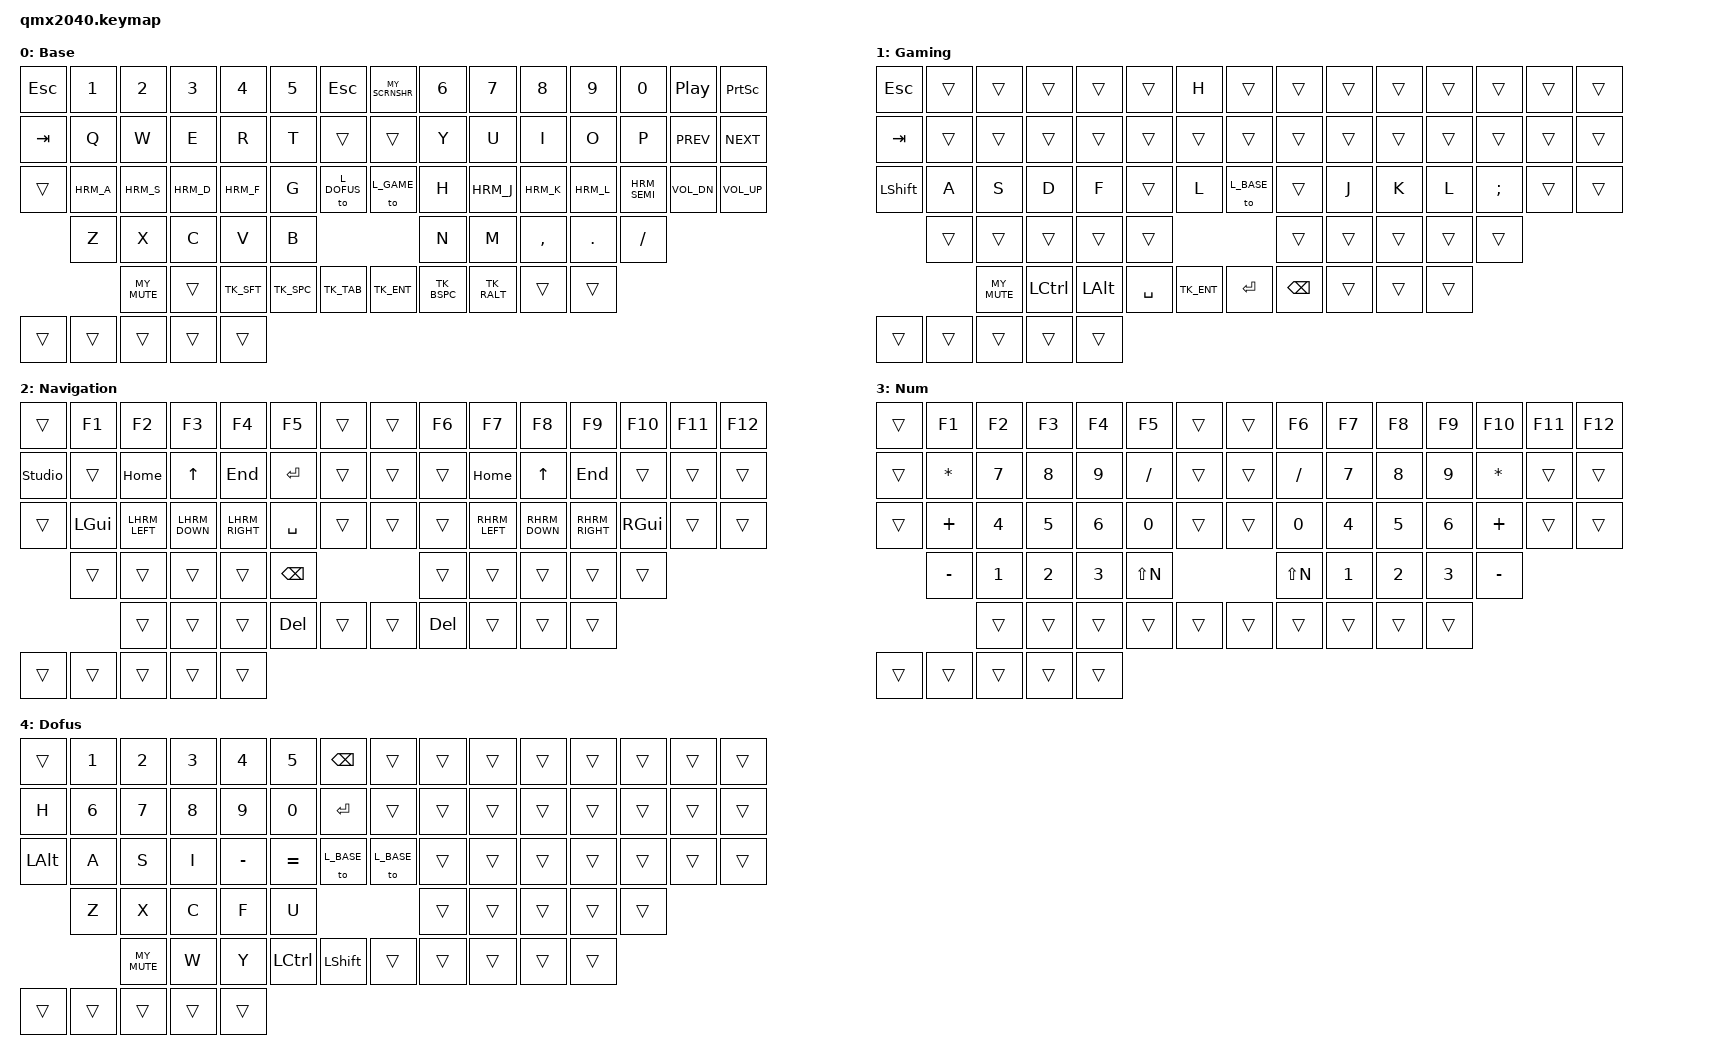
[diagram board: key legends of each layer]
#include <behaviors.dtsi>
#include <dt-bindings/zmk/keys.h>

#include <dt-bindings/zmk/oskey.h>
#include <behaviors/oskey.dtsi>


#include "config.h"



&sl { ignore-modifiers; }; // keep one-shot-mods when chained into a one-shot-layer
&sk { quick-release; };    // must-have! (lots of false positives otherwise)

// add our common tap-hold parametesr to the default options
&mt {
  tapping-term-ms = <SHORT_TAPPING_TERM>;
  quick-tap-ms = <QUICK_TAP>;
};

&lt {
  tapping-term-ms = <TAPPING_TERM>;
  quick-tap-ms = <QUICK_TAP>;
};

/ {
  behaviors {

    hrm: homerow_mods {
      compatible = "zmk,behavior-hold-tap";
      #binding-cells = <2>;
      tapping-term-ms = <TAPPING_TERM>;
      quick-tap-ms = <QUICK_TAP>;
      flavor = "tap-preferred";
      bindings = <&kp>, <&kp>;
    };

    sc: space_cadet { // same as lt, but with hold-preferred
      compatible = "zmk,behavior-hold-tap";
      #binding-cells = <2>;
      tapping-term-ms = <SHORT_TAPPING_TERM>;
      quick-tap-ms = <QUICK_TAP>;
      flavor = "hold-preferred";
      bindings = <&mo>, <&kp>;
    };

    // in case i want to do keyboard emulation of ergol
    // like ZMK's sticky layer (sl) but with a more robust timing
    // osl: one_shot_layer {
    //   compatible = "zmk,behavior-macro-one-param";
    //   #binding-cells = <1>;
    //   tap-ms = <0>;
    //   wait-ms = <0>;
    //   bindings = <&macro_param_1to1>, <&macro_tap &sl MACRO_PLACEHOLDER>;
    // };
    //  
    // bsl: better_sticky_layer {
    //   compatible = "zmk,behavior-hold-tap";
    //   #binding-cells = <2>;
    //   tapping-term-ms = <TAPPING_TERM>;
    //   flavor = "tap-preferred";
    //   bindings = <&mo>, <&osl>;
    // };

    // like ZMK's sticky key (sk) but with a more robust timing
    osm: one_shot_modifier {
      compatible = "zmk,behavior-macro-one-param";
      #binding-cells = <1>;
      tap-ms = <0>;
      wait-ms = <0>;
      bindings = <&macro_param_1to1>, <&macro_tap &sk MACRO_PLACEHOLDER>;
    };

    bsk: better_sticky_key {
      compatible = "zmk,behavior-hold-tap";
      #binding-cells = <2>;
      tapping-term-ms = <TAPPING_TERM>;
      flavor = "tap-preferred";
      bindings = <&kp>, <&osm>;
    };

    bsk_shift: bsk_shift {
      compatible = "zmk,behavior-mod-morph";
      #binding-cells = <0>;
      bindings  = <&EZ_SK(LSHFT)>, <&kp CAPSLOCK>;
      mods      = <MOD_RALT>;
      keep-mods = <MOD_RALT>;
    };

  };


  combos {
    compatible = "zmk,combos";

    combo_esc {
      timeout-ms = <30>;
      layers = <L_BASE>;
      key-positions = <39 40>;
      bindings = <&kp ESC>;
    };

  };


  keymap {
    compatible = "zmk,keymap";

    base_layer: base_layer {
      display-name = "Base";
      bindings = <
        &kp ESC   &kp N1 &kp N2  &kp N3 &kp N4 &kp N5 &kp ESC       MY_SCRNSHR &kp N6  &kp N7  &kp N8    &kp N9  &kp N0     &kp C_PP     &kp PSCRN
        &kp TAB   &kp Q  &kp W   &kp E  &kp R  &kp T  &trans        &trans     &kp Y   &kp U   &kp I     &kp O   &kp P      &kp C_PREV   &kp C_NEXT
        &trans    HRM_A  HRM_S   HRM_D  HRM_F  &kp G  &to L_DOFUS   &to L_GAME &kp H   HRM_J   HRM_K     HRM_L   HRM_SEMI   &kp C_VOL_DN &kp C_VOL_UP
                  &kp Z  &kp X   &kp C  &kp V  &kp B                           &kp N   &kp M   &kp COMMA &kp DOT &kp FSLH
                         MY_MUTE &trans TK_SFT TK_SPC TK_TAB        TK_ENT     TK_BSPC TK_RALT &trans    &trans
          &trans  &trans  &trans  &trans  &trans
      >;
    };


    layer_gaming: layer_gaming {
      display-name = "Gaming";
      bindings = <
        &kp ESC   &trans  &trans  &trans &trans   &trans  &kp H         &trans     &trans    &trans &trans &trans &trans    &trans &trans
        &kp TAB   &trans  &trans  &trans &trans   &trans  &trans        &trans     &trans    &trans &trans &trans &trans    &trans &trans
        &kp LSHFT &kp A   &kp S   &kp D  &kp F    &trans  &kp L         &to L_BASE &trans    &kp J  &kp K  &kp L  &kp SEMI  &trans &trans
                  &trans  &trans  &trans &trans   &trans                           &trans    &trans &trans &trans &trans
                          MY_MUTE &kp LCTL &kp LALT &kp SPC TK_ENT        &kp ENTER  &kp BSPC  &trans &trans &trans
          &trans  &trans  &trans  &trans  &trans
      >;
    };


    layer_nav: layer_nav {
      display-name = "Navigation";
      bindings = <
        &trans         &kp F1    &kp F2    &kp F3    &kp F4     &kp F5    &trans     &trans &kp F6  &kp F7    &kp F8    &kp F9     &kp F10   &kp F11 &kp F12
        &studio_unlock &trans    &kp HOME  &kp UP    &kp END    &kp RET   &trans     &trans &trans  &kp HOME  &kp UP    &kp END    &trans    &trans  &trans
        &trans         &kp LGUI  LHRM_LEFT LHRM_DOWN LHRM_RIGHT &kp SPC   &trans     &trans &trans  RHRM_LEFT RHRM_DOWN RHRM_RIGHT &kp RGUI  &trans  &trans
                       &trans    &trans    &trans    &trans     &kp BSPC                    &trans  &trans    &trans    &trans     &trans
                                 &trans    &trans    &trans     &kp DEL   &trans     &trans &kp DEL &trans    &trans    &trans
          &trans  &trans  &trans  &trans  &trans
      >;
    };


    layer_num: layer_num {
      display-name = "Num";
      bindings = <
        &trans &kp F1    &kp F2 &kp F3 &kp F4 &kp F5    &trans    &trans &kp F6    &kp F7 &kp F8 &kp F9 &kp F10   &kp F11 &kp F12
        &trans &kp STAR  &kp N7 &kp N8 &kp N9 &kp SLASH &trans    &trans &kp SLASH &kp N7 &kp N8 &kp N9 &kp STAR  &trans &trans
        &trans &kp PLUS  &kp N4 &kp N5 &kp N6 &kp N0    &trans    &trans &kp N0    &kp N4 &kp N5 &kp N6 &kp PLUS  &trans &trans
               &kp MINUS &kp N1 &kp N2 &kp N3 &kp LS(N)                  &kp LS(N) &kp N1 &kp N2 &kp N3 &kp MINUS
                         &trans &trans &trans &trans    &trans    &trans &trans    &trans &trans &trans
          &trans  &trans  &trans  &trans  &trans
      >;
    };


    layer_dofus: layer_dofus {
      display-name = "Dofus";
      bindings = <
        &trans   &kp N1  &kp N2 &kp N3 &kp N4    &kp N5    &kp BSPC         &trans &trans &trans &trans &trans &trans &trans &trans
        &kp H    &kp N6  &kp N7 &kp N8 &kp N9    &kp N0    &kp RET          &trans &trans &trans &trans &trans &trans &trans &trans
        &kp LALT &kp A   &kp S  &kp I  &kp MINUS &kp EQUAL &to L_BASE   &to L_BASE &trans &trans &trans &trans &trans &trans &trans
                 &kp Z   &kp X  &kp C  &kp F     &kp U                             &trans &trans &trans &trans &trans
                 MY_MUTE &kp W  &kp Y  &kp LCTL  &kp LSHFT                  &trans &trans &trans &trans &trans
          &trans  &trans  &trans  &trans  &trans
      >;
    };

  };
};
